# STM32F303 register map
File version: 1.9
CPU: CM4 r1p0, little endian, MPU, FPU, 3 interrupt priority bits
Registers are 32-bit, read-write, reset 0x0 unless marked. A register's access mark holds for its fields unless they carry their own. Offsets are from the block's base; [hi:lo] are bit positions.

## TIM16 — General-purpose-timers
Base 0x40014400
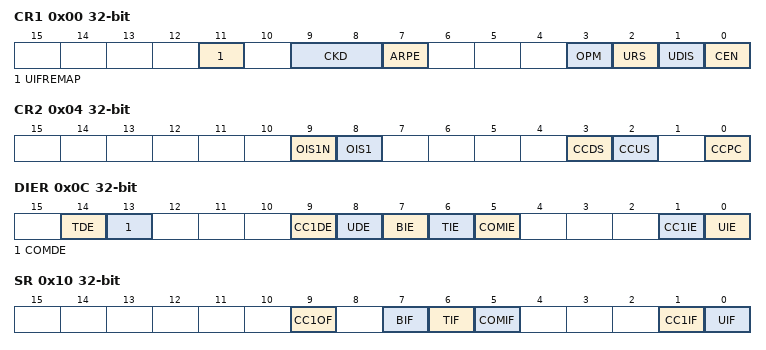
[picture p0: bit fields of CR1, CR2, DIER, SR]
0x00 CR1 — control register 1
  [11] UIFREMAP — UIF status bit remapping
  [9:8] CKD — Clock division
  [7] ARPE — Auto-reload preload enable
  [3] OPM — One-pulse mode
  [2] URS — Update request source
  [1] UDIS — Update disable
  [0] CEN — Counter enable
0x04 CR2 — control register 2
  [9] OIS1N — Output Idle state 1
  [8] OIS1 — Output Idle state 1
  [3] CCDS — Capture/compare DMA selection
  [2] CCUS — Capture/compare control update selection
  [0] CCPC — Capture/compare preloaded control
0x0C DIER — DMA/Interrupt enable register
  [14] TDE — Trigger DMA request enable
  [13] COMDE — COM DMA request enable
  [9] CC1DE — Capture/Compare 1 DMA request enable
  [8] UDE — Update DMA request enable
  [7] BIE — Break interrupt enable
  [6] TIE — Trigger interrupt enable
  [5] COMIE — COM interrupt enable
  [1] CC1IE — Capture/Compare 1 interrupt enable
  [0] UIE — Update interrupt enable
0x10 SR — status register
  [9] CC1OF — Capture/Compare 1 overcapture flag
  [7] BIF — Break interrupt flag
  [6] TIF — Trigger interrupt flag
  [5] COMIF — COM interrupt flag
  [1] CC1IF — Capture/compare 1 interrupt flag
  [0] UIF — Update interrupt flag
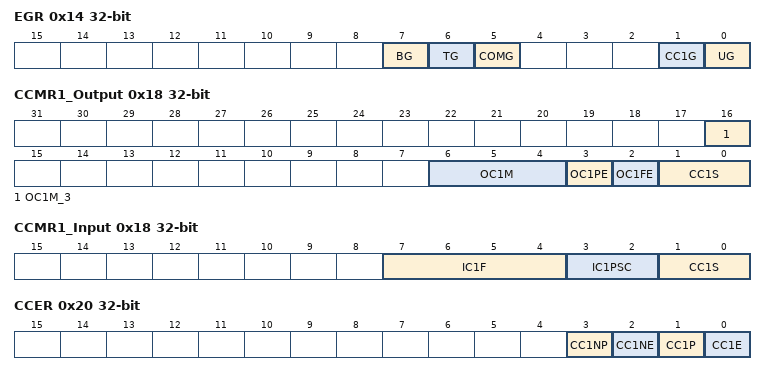
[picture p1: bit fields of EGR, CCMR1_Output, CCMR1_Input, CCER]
0x14 EGR wo — event generation register
  [7] BG — Break generation
  [6] TG — Trigger generation
  [5] COMG — Capture/Compare control update generation
  [1] CC1G — Capture/compare 1 generation
  [0] UG — Update generation
0x18 CCMR1_Output — capture/compare mode register (output mode)
  [16] OC1M_3 — Output Compare 1 mode
  [6:4] OC1M — Output Compare 1 mode
  [3] OC1PE — Output Compare 1 preload enable
  [2] OC1FE — Output Compare 1 fast enable
  [1:0] CC1S — Capture/Compare 1 selection
0x18 CCMR1_Input (alternate view of CCMR1_Output) — capture/compare mode register 1 (input mode)
  [7:4] IC1F — Input capture 1 filter
  [3:2] IC1PSC — Input capture 1 prescaler
  [1:0] CC1S — Capture/Compare 1 selection
0x20 CCER — capture/compare enable register
  [3] CC1NP — Capture/Compare 1 output Polarity
  [2] CC1NE — Capture/Compare 1 complementary output enable
  [1] CC1P — Capture/Compare 1 output Polarity
  [0] CC1E — Capture/Compare 1 output enable
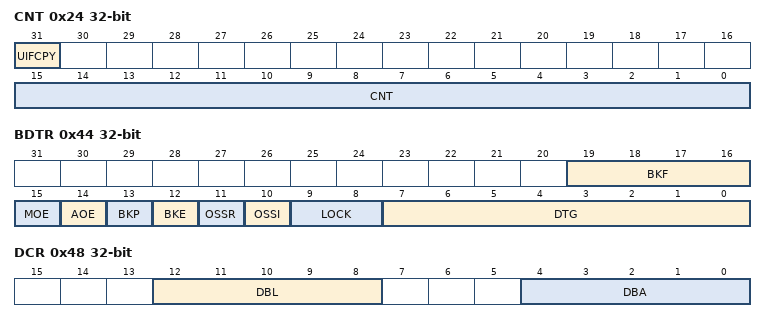
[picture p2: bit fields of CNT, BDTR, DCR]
0x24 CNT access per field — counter
  [31] UIFCPY ro — UIF Copy
  [15:0] CNT rw — counter value
0x28 PSC — prescaler
  [15:0] PSC — Prescaler value
0x2C ARR — auto-reload register
  [15:0] ARR — Auto-reload value
0x30 RCR — repetition counter register
  [7:0] REP — Repetition counter value
0x34 CCR1 — capture/compare register 1
  [15:0] CCR1 — Capture/Compare 1 value
0x44 BDTR — break and dead-time register
  [19:16] BKF — Break filter
  [15] MOE — Main output enable
  [14] AOE — Automatic output enable
  [13] BKP — Break polarity
  [12] BKE — Break enable
  [11] OSSR — Off-state selection for Run mode
  [10] OSSI — Off-state selection for Idle mode
  [9:8] LOCK — Lock configuration
  [7:0] DTG — Dead-time generator setup
0x48 DCR — DMA control register
  [12:8] DBL — DMA burst length
  [4:0] DBA — DMA base address
0x4C DMAR — DMA address for full transfer
  [15:0] DMAB — DMA register for burst accesses
0x50 OR — option register

## TIM17 — General purpose timer
Base 0x40014800
Registers as TIM16, without OR.

## SPI1 — Serial peripheral interface/Inter-IC sound
Base 0x40013000
Same registers: SPI2 0x40003800, SPI3 0x40003C00, SPI4 0x40013C00
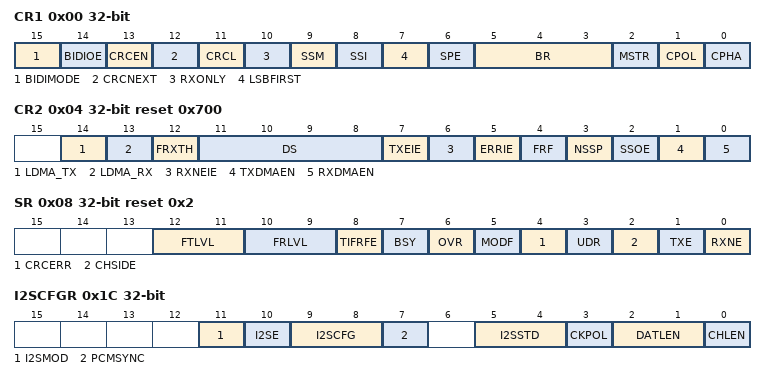
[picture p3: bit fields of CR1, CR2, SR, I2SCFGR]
0x00 CR1 — control register 1
  [15] BIDIMODE — Bidirectional data mode enable
  [14] BIDIOE — Output enable in bidirectional mode
  [13] CRCEN — Hardware CRC calculation enable
  [12] CRCNEXT — CRC transfer next
  [11] CRCL — CRC length
  [10] RXONLY — Receive only
  [9] SSM — Software slave management
  [8] SSI — Internal slave select
  [7] LSBFIRST — Frame format
  [6] SPE — SPI enable
  [5:3] BR — Baud rate control
  [2] MSTR — Master selection
  [1] CPOL — Clock polarity
  [0] CPHA — Clock phase
0x04 CR2 reset 0x700 — control register 2
  [14] LDMA_TX — Last DMA transfer for transmission
  [13] LDMA_RX — Last DMA transfer for reception
  [12] FRXTH — FIFO reception threshold
  [11:8] DS — Data size
  [7] TXEIE — Tx buffer empty interrupt enable
  [6] RXNEIE — RX buffer not empty interrupt enable
  [5] ERRIE — Error interrupt enable
  [4] FRF — Frame format
  [3] NSSP — NSS pulse management
  [2] SSOE — SS output enable
  [1] TXDMAEN — Tx buffer DMA enable
  [0] RXDMAEN — Rx buffer DMA enable
0x08 SR access per field reset 0x2 — status register
  [12:11] FTLVL ro — FIFO transmission level
  [10:9] FRLVL ro — FIFO reception level
  [8] TIFRFE ro — TI frame format error
  [7] BSY ro — Busy flag
  [6] OVR ro — Overrun flag
  [5] MODF ro — Mode fault
  [4] CRCERR rw — CRC error flag
  [3] UDR ro — Underrun flag
  [2] CHSIDE ro — Channel side
  [1] TXE ro — Transmit buffer empty
  [0] RXNE ro — Receive buffer not empty
0x0C DR — data register
  [15:0] DR — Data register
0x10 CRCPR reset 0x7 — CRC polynomial register
  [15:0] CRCPOLY
0x14 RXCRCR ro — RX CRC register
  [15:0] RxCRC
0x18 TXCRCR ro — TX CRC register
  [15:0] TxCRC
0x1C I2SCFGR — I2S configuration register
  [11] I2SMOD — I2S mode selection
  [10] I2SE — I2S Enable
  [9:8] I2SCFG — I2S configuration mode
  [7] PCMSYNC — PCM frame synchronization
  [5:4] I2SSTD — I2S standard selection
  [3] CKPOL — Steady state clock polarity
  [2:1] DATLEN — Data length to be transferred
  [0] CHLEN — Channel length (number of bits per audio channel)
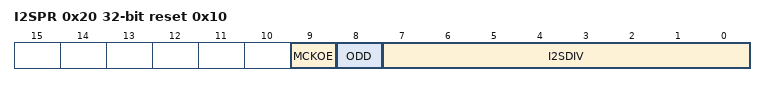
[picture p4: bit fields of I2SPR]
0x20 I2SPR reset 0x10 — I2S prescaler register
  [9] MCKOE — Master clock output enable
  [8] ODD — Odd factor for the prescaler
  [7:0] I2SDIV — I2S Linear prescaler

## I2S2ext — Serial peripheral interface/Inter-IC sound
Base 0x40003400
Same registers: I2S3ext 0x40004000
Registers as SPI1; these are added or differ:
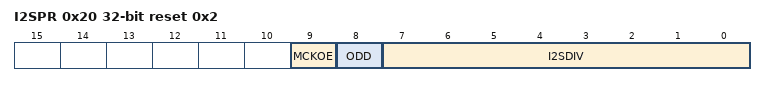
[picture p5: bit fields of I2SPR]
0x20 I2SPR reset 0x2 — I2S prescaler register
  [9] MCKOE — Master clock output enable
  [8] ODD — Odd factor for the prescaler
  [7:0] I2SDIV — I2S Linear prescaler
